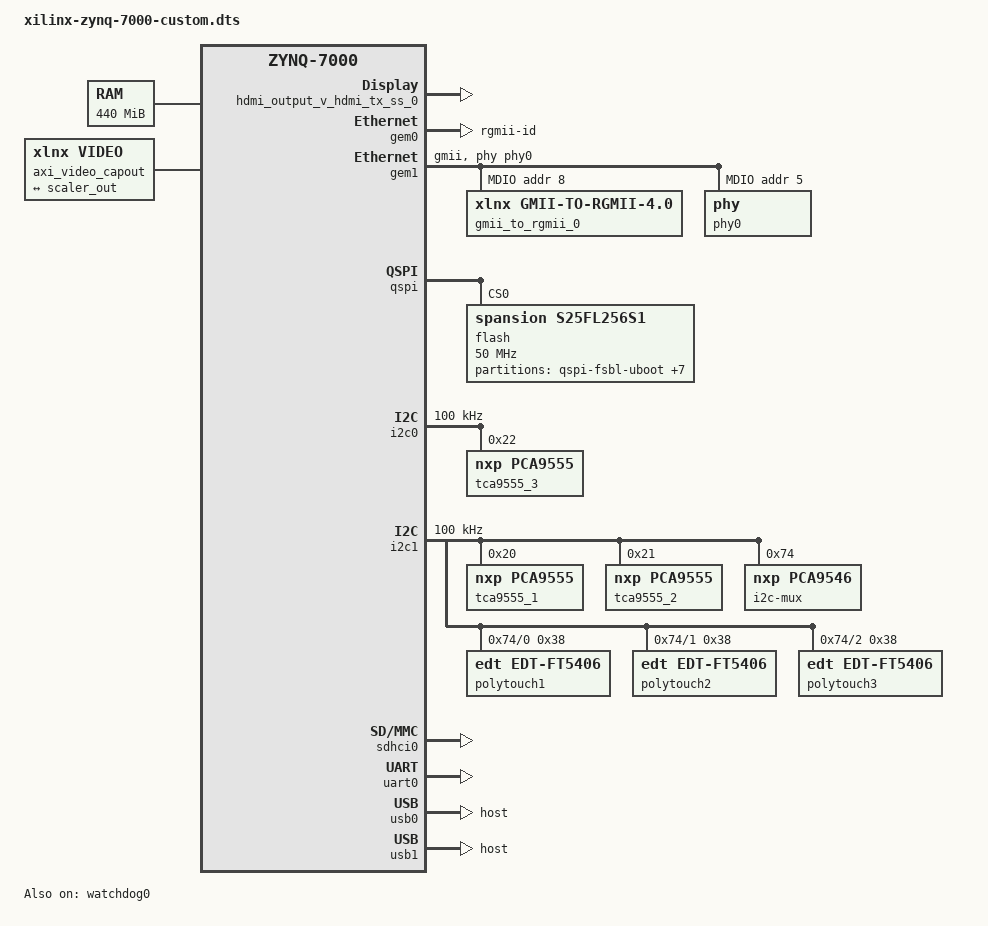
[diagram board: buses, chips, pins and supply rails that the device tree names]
/*
 * CAUTION: This file is automatically generated by Xilinx.
 * Version: HSI 2016.3
 * Today is: Wed Jan 11 12:34:24 2017
*/


/dts-v1/;
/include/ "zynq-7000-custom.dtsi"
/include/ "pl.dtsi"
/ {
	cpus {
		cpu@0 {
			operating-points = <666666 1000000 333333 1000000>;
		};
	};
	chosen {
		bootargs = "console=ttyPS0,115200";
	};
	aliases {
		ethernet0 = &gem0;
		ethernet1 = &gem1;
		serial0 = &uart0;
		spi0 = &qspi;
	};
	memory {
		device_type = "memory";
		reg = <0x0 0x1b800000>; //for accommodating vpss ram requirement of 64MB
	};

    reserved-memory {
		#address-cells = <1>;
		#size-cells = <1>;
		ranges;

		/* global autoconfigured region for contiguous allocations */
		linux,cma {
			compatible = "shared-dma-pool";
			reusable;
			size = <0x2000000>;
			alignment = <0x2000>;
			linux,cma-default;
		};
	};
};

/{

	vid_stream_clk:clk{
		compatible = "fixed-clock";
		#clock-cells = <0>;
		clock-frequency = <150000000>;
	};
	misc_clk_2:clk1{
		compatible = "fixed-clock";
		#clock-cells = <0>;
		clock-frequency = <150000000>;
	};

scaler_1:scaler@43C40000 {
				#address-cells = <1>;
				#size-cells = <1>;
			 //compatible = "xlnx,v-vpss-scaler-1.0";
			 compatible = "xlnx,v-vpss-scaler";
			// reg = <0x0 0x43d00000 0x0 0x100000>;
			 //for full fledged config reg = <0x43d00000 0x100000>;
			 //deinterlacer only mode clubbed with general purpose fpga regs too
			 //prash@woh:: just twant to avoid fpga rgion which start at 0x43c00000 so started with 0x43c10000 and size rediced from
			 //0x30000 to 0x20000
			 //64k@0x43c20000 is deinterlacer
			 //64K@43000000	is vdma
			 //256K@43c40000 is vpss scaler 
			 reg = <0x43c20000 0x10000
			 		0x43000000 0x10000
					0x43C40000 0x40000>;
			 clocks = <&vid_stream_clk>, <&misc_clk_2>;
			 clock-names = "aclk_axis", "aclk_ctrl";
			 xlnx,num-hori-taps = <6>;
			 xlnx,num-vert-taps = <6>;
			 xlnx,pix-per-clk = <1>;
			 /*reset-gpios = <&gpio 87 1>;*/
			 xlnx,max-width = <2048>;
			 xlnx,max-height = <1080>;



			 ports {
				#address-cells = <1>;
				#size-cells = <0>;
				/*
				 port@0 {
					 // Sink Pad 
					 reg = <0>;
					 xlnx,video-format = <0>;//legacy<XVIP_VF_RBG>;
					 xlnx,video-width = <10>;
					 scaler_in: endpoint {
			         	remote-endpoint = <&vid_out0>;
		   			};
				 };
				 */
				 port@0 {
					 /* Sink Pad */
					 reg = <0>;
					 xlnx,video-format = <0>;//legacy<XVIP_VF_RBG>;
					 xlnx,video-width = <10>;
					 
				 };
				 /*
				 port@1 {
					 // Source Pad 
					 reg = <1>;

					 xlnx,video-format = <0>;
					 xlnx,video-width = <10>;
				 };
				 */
				 
				 port@1 {
					 // Source Pad 
					 reg = <1>;
					 xlnx,video-format = <0>;//legacy <XVIP_VF_YUV_422>;
					 xlnx,video-width = <10>;
					 scaler_out: endpoint {
						remote-endpoint = <&vid_in0>;
					};
				 };
				 
			 };

		 };
axi_vdma_1: dma@40400000 {
			   #dma-cells = <1>;
			   clock-names = "s_axi_lite_aclk", "m_axi_sg_aclk", "m_axi_mm2s_aclk", "m_axi_s2mm_aclk";
			   clocks = <&clkc 15>, <&clkc 15>, <&clkc 15>, <&clkc 15>;
			   compatible = "xlnx,axi-dma-1.00.a";
			   interrupt-parent = <&intc>;
			   interrupts = <0 29 4 0 30 4>;
			   reg = <0x40400000 0x10000>;
			   xlnx,addrwidth = <0x20>;
			   xlnx,include-sg ;
			   dma-channel@40400000 {
				   compatible = "xlnx,axi-dma-mm2s-channel";
				   dma-channels = <0x1>;
				   interrupts = <0 29 4>;
				   xlnx,datawidth = <0x20>;
				   xlnx,device-id = <0x0>;
				   xlnx,include-dre ;
			   };

		   };
		   /*
		 axi_video_cap {
			 compatible = "xlnx,video";
			 dmas = <&axi_vdma_1 1>;
			 dma-names = "port0";

			ports {
				#address-cells = <1>;
				#size-cells = <0>;

				 port@0 {
					 reg = <0>;
					 direction = "output";
					vid_out0: endpoint {
			   			remote-endpoint = <&scaler_in>; //scalers input port is connected to output of vid_in
		   			};
				 };

			 };
		 };
		 */
		 
		 axi_video_capout {
			 compatible = "xlnx,video";
			 dmas = <&axi_vdma_1 1>;
			 dma-names = "port0";

			 ports {
				#address-cells = <1>;
				#size-cells = <0>;

				 port@0 {
					 reg = <0>;
					 direction = "input";
					vid_in0: endpoint {
			  			remote-endpoint = <&scaler_out>; //scalers input port is connected to output of vid_in
		  			};
				 };

			 };
		 };
		 /*
		 vcap_tpg_in:tpg@40050000 {
			compatible = "xlnx,v-tpg-6.0", "xlnx,v-tpg-5.0";
			reg = <0x40050000 0x10000>;
			clocks = <&clkc 15>;
			
			ports {
				#address-cells = <1>;
				#size-cells = <0>;

				port@0 {
					reg = <0>;

					xlnx,video-format = <0>;
					xlnx,video-width = <10>;

					tpg_in: endpoint {
						remote-endpoint = <&scaler_out>;
					};
				};
		 	};
		};	
		 */

};

/{
hdmi_output_v_hdmi_tx_ss_0: v_hdmi_tx_ss@a0020000 {
			compatible = "xlnx,v-hdmi-tx-ss-3.0";
			reg = <0x0 0xa0100000 0x0 0x100000>, <0x0 0xa0280000 0x0 0x10000>;
			reg-names = "hdmi-txss", "hdcp1x-keymngmt";		
			};
v_mix_0: v_mix@43C10000 {
			 compatible = "xlnx,drm,video-mixer";
			 reg = <0x43c10000 0x10000>;
			 xlnx,bpc = <8>;
			 xlnx,ppc = <1>;
			 xlnx,num-layers = <2>;
			 xlnx,dma-addr-width=<32>;
			 xlnx,encoder-slave = <&hdmi_output_v_hdmi_tx_ss_0>;
	         xlnx,connector-type = "HDMIA";

mixer_master_layer: layer_0 {
						xlnx,layer-id = <0>;
		//				xlnx,vformat = "abgr8888"; 
		//				xlnx,vformat = "rgba8888"; 
					 	xlnx,vformat = "argb8888"; 
						xlnx,layer-streaming;
					 	xlnx,layer-primary;
						/*prash@woh:: this values doesnt mean that bkg layer or layer_0 will have resolution of 480x270
						background layer is always to 1920x1080 which is native resolution of video mixer as set from vivado
						480x270 means 4x scaling can be enabled.*/	
						xlnx,layer-width = <320>;
						xlnx,layer-height = <240>;
					};
mixer_overlay_1: layer_1 {
					 xlnx,layer-id = <1>;
		//			 xlnx,vformat = "abgr8888";
		//			 xlnx,vformat = "rgba8888"; 
					 xlnx,vformat = "argb8888"; 
					 xlnx,layer-width = <320>;
					 xlnx,layer-height = <240>;
			//		 xlnx,layer-scale;
					 xlnx,layer-alpha;
				 };
		 };
v_mix_1: v_mix@43C30000 {
			 compatible = "xlnx,drm,video-mixer";
			 reg = <0x43c30000 0x10000>;
			 xlnx,bpc = <8>;
			 xlnx,ppc = <1>;
			 xlnx,num-layers = <2>;
			 xlnx,dma-addr-width=<32>;
			 xlnx,encoder-slave = <&hdmi_output_v_hdmi_tx_ss_0>;
	         xlnx,connector-type = "HDMIA";

mixer_master_layer11: layer_0 {
						xlnx,layer-id = <0>;
		//				xlnx,vformat = "abgr8888"; 
		//				xlnx,vformat = "rgba8888"; 
					 	xlnx,vformat = "argb8888"; 
						xlnx,layer-streaming;
					 	xlnx,layer-primary;
						/*prash@woh:: this values doesnt mean that bkg layer or layer_0 will have resolution of 480x270
						background layer is always to 1920x1080 which is native resolution of video mixer as set from vivado
						480x270 means 4x scaling can be enabled.*/	
						xlnx,layer-width = <240>;
						xlnx,layer-height = <320>;
					};
mixer_overlay_11: layer_1 {
					 xlnx,layer-id = <1>;
		//			 xlnx,vformat = "abgr8888";
		//			 xlnx,vformat = "rgba8888"; 
					 xlnx,vformat = "argb8888"; 
					 xlnx,layer-width = <240>;
					 xlnx,layer-height = <320>;
			//		 xlnx,layer-scale;
					 xlnx,layer-alpha;
				 };
		 };
v_mix_2: v_mix@43C80000 {
			 compatible = "xlnx,drm,video-mixer";
			 reg = <0x43c80000 0x10000>;
			 xlnx,bpc = <8>;
			 xlnx,ppc = <1>;
			 xlnx,num-layers = <2>;
			 xlnx,dma-addr-width=<32>;
			 xlnx,encoder-slave = <&hdmi_output_v_hdmi_tx_ss_0>;
			 xlnx,connector-type = "HDMIA";

mixer_master_layer21: layer_0 {
						  xlnx,layer-id = <0>;
						  //				xlnx,vformat = "abgr8888"; 
						  //				xlnx,vformat = "rgba8888"; 
						  xlnx,vformat = "argb8888"; 
						  xlnx,layer-streaming;
						  xlnx,layer-primary;
						  /*prash@woh:: this values doesnt mean that bkg layer or layer_0 will have resolution of 480x270
							background layer is always to 1920x1080 which is native resolution of video mixer as set from vivado
							480x270 means 4x scaling can be enabled.*/	
						  xlnx,layer-width = <240>;
						  xlnx,layer-height = <320>;
					  };
mixer_overlay_21: layer_1 {
					  xlnx,layer-id = <1>;
					  //			 xlnx,vformat = "abgr8888";
					  //			 xlnx,vformat = "rgba8888"; 
					  xlnx,vformat = "argb8888"; 
					  xlnx,layer-width = <240>;
					  xlnx,layer-height = <320>;
					  //		 xlnx,layer-scale;
					  xlnx,layer-alpha;
				  };
		 };
/*		 
v_mix_1: v_mix@43C10000 {
			 compatible = "xlnx,drm,video-mixer";
			 reg = <0x43c10000 0x10000>;
			 xlnx,bpc = <8>;
			 xlnx,ppc = <1>;
			 xlnx,num-layers = <2>;
			 xlnx,dma-addr-width=<32>;
			 xlnx,encoder-slave = <&hdmi_output_v_hdmi_tx_ss_0>;
	         xlnx,connector-type = "HDMIA";

mixer_master_layer1: layer_0 {
						xlnx,layer-id = <0>;
		//				xlnx,vformat = "abgr8888"; 
		//				xlnx,vformat = "rgba8888"; 
					 	xlnx,vformat = "argb8888"; 
						xlnx,layer-streaming;
					 	xlnx,layer-primary;
						/prash@woh:: this values doesnt mean that bkg layer or layer_0 will have resolution of 480x270
						background layer is always to 1920x1080 which is native resolution of video mixer as set from vivado
						480x270 means 4x scaling can be enabled./	
						xlnx,layer-width = <480>;
						xlnx,layer-height = <270>;
					};
mixer_overlay_2: layer_1 {
					 xlnx,layer-id = <1>;
		//			 xlnx,vformat = "abgr8888";
		//			 xlnx,vformat = "rgba8888"; 
					 xlnx,vformat = "argb8888"; 
					 xlnx,layer-width = <480>;
					 xlnx,layer-height = <270>;
					 xlnx,layer-scale;
					 xlnx,layer-alpha;
				 };				
		 };*/
};

&gem0 {
	local-mac-address = [00 0a 35 00 00 00];
	phy-mode = "rgmii-id";
	status = "okay";
	xlnx,ptp-enet-clock = <0x69f6bcb>;
};


&gem1 {
	gmii2rgmii-phy-handle = <&gmii_to_rgmii_0>;
	phy-handle = <&phy0>;
	
	local-mac-address = [00 0a 35 00 00 01];
	phy-mode = "gmii";
	status = "okay";
	xlnx,ptp-enet-clock = <0x69f6bcb>;
	ps7_ethernet_1_mdio: mdio {
		#address-cells = <1>;
		#size-cells = <0>;
		gmii_to_rgmii_0: phy@8 {
		compatible = "xlnx,gmii-to-rgmii-4.0";
		device_type = "ethernet-phy";
		reg = <8>;
		phy-handle = <&phy0>;
		};
		
		phy0: phy@5 {
                    device_type = "ethernet-phy";
                    reg = <0x5>;
                } ;
	};
};
/*
&gem1 {
	local-mac-address = [00 0a 35 00 00 01];
	phy-mode = "gmii";
	status = "okay";
	xlnx,ptp-enet-clock = <0x69f6bcb>;
};*/
&qspi {
	u-boot,dm-pre-reloc;
	status = "okay";
	is-dual = <0>;
	num-cs = <1>;
	flash@0 {
		compatible = "spansion,s25fl256s1", "jedec,spi-nor";
		reg = <0x0>;
		spi-tx-bus-width = <1>;
		spi-rx-bus-width = <4>;
		spi-max-frequency = <50000000>;
		#address-cells = <1>;
		#size-cells = <1>;
	    partition@qspi-fsbl-uboot {
			label = "qspi-fsbl-uboot";
			reg = <0x0 0xB0000>;
		};
        partition@qspi-fsbl-uboot-failsafe {
			label = "qspi-fsbl-uboot-failsafe";
			reg = <0x00B0000 0x0B0000>;
		};
		partition@qspi-linux {
			label = "qspi-linux";
			reg = <0x160000 0x380000>;
		};
		partition@qspi-device-tree {
			label = "qspi-device-tree";
			reg = <0x4E0000 0x10000>;
		};
		partition@qspi-rootfs {
			label = "qspi-rootfs";
			reg = <0x5F0000 0x480000>;
		};
		partition@qspi-bitstream {
			label = "qspi-bitstream";
			reg = <0xA70000 0x580000>;
		};
		partition@qspi-scratchpad {
			label = "qspi-scratchpad";
			reg = <0x4F0000 0x100000>;
		};
        partition@qspi-app {
			label = "qspi-app";
			reg = <0xFF0000 0x1000000>;
		};
	};
};

&i2c0 {
    clock-frequency = <100000>;
    status = "okay";
	tca9555_3: gpio@23 {
		compatible = "nxp,pca9555";
		reg = <0x22>;
		gpio-controller;
		#gpio-cells = <2>;
	};

};

&i2c1 {
	clock-frequency = <100000>;
	status = "okay";
    tca9555_1: gpio@21 {
		compatible = "nxp,pca9555";
		reg = <0x20>;
		gpio-controller;
		#gpio-cells = <2>;
	};
    tca9555_2: gpio@22 {
		compatible = "nxp,pca9555";
		reg = <0x21>;
		gpio-controller;
		#gpio-cells = <2>;
	};
/*
    i2c-mux@77 {
    	compatible = "nxp,pca9546";
		#address-cells = <1>;
		#size-cells = <0>;
		reg = <0x77>;
    };
*/
    i2c-mux@74 {
        compatible = "nxp,pca9546";
		#address-cells = <1>;
		#size-cells = <0>;
		reg = <0x74>;
        //This is Touch_b device at second i2c after mux 
        i2c@1 {
            #address-cells = <1>;
            #size-cells = <0>;
            reg = <0>;
            polytouch1: edt-ft5x06@38 {
		        compatible = "edt,edt-ft5406", "edt,edt-ft5x06","focaltech,ft6236";
                reg = <0x38>;
                interrupt-parent = <&intc>;
                interrupts = <0 29 4>;      //Interrupt no. is 61 from PL to PS 61-32=29 4 = Level sensitive, active high
                touchscreen-size-x = <320>;
                touchscreen-size-y = <240>;
            };
        };
		i2c@2 {
            #address-cells = <1>;
            #size-cells = <0>;
            reg = <1>;
            polytouch2: edt-ft5x06@38 {
		        compatible = "edt,edt-ft5406", "edt,edt-ft5x06","focaltech,ft6236";
                reg = <0x38>;
                interrupt-parent = <&intc>;
                interrupts = <0 30 4>;      //Interrupt no. is 61 from PL to PS 61-32=29 4 = Level sensitive, active high
                touchscreen-size-x = <240>;
                touchscreen-size-y = <320>;
            };
        };
		i2c@3 {
            #address-cells = <1>;
            #size-cells = <0>;
            reg = <2>;
            polytouch3: edt-ft5x06@38 {
		        compatible = "edt,edt-ft5406", "edt,edt-ft5x06","focaltech,ft6236";
                reg = <0x38>;
                interrupt-parent = <&intc>;
                interrupts = <0 31 4>;      //Interrupt no. is 61 from PL to PS 61-32=29 4 = Level sensitive, active high
                touchscreen-size-x = <240>;
                touchscreen-size-y = <320>;
            };
        };
    };


};


&intc {
	num_cpus = <2>;
	num_interrupts = <96>;
};
&sdhci0 {
	status = "okay";
	xlnx,has-cd = <0x0>;
	xlnx,has-power = <0x0>;
	xlnx,has-wp = <0x0>;
};
&uart0 {
	device_type = "serial";
	port-number = <0>;
	status = "okay";
};
&clkc {
	fclk-enable = <0x1>;
	ps-clk-frequency = <33333333>;
};
&watchdog0 {
    status = "okay";
    reset-on-timeout;
};
&usb0 {
    status = "okay";
    dr_mode = "host";
    
};
&usb1 {
    status = "okay";
    dr_mode = "host";
};
